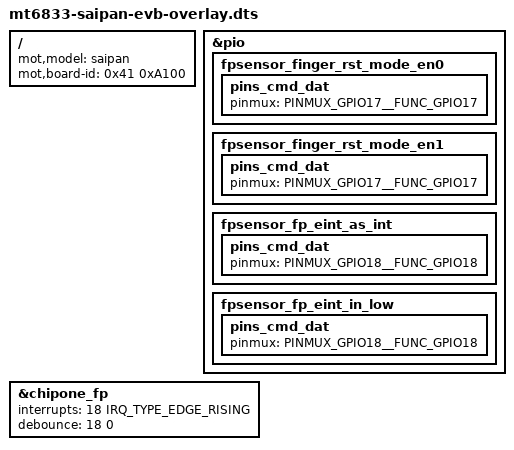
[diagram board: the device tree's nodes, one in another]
/* Copyright (c) 2019, Motorola Mobility Inc. All rights reserved.
 *
 * This program is free software; you can redistribute it and/or modify
 * it under the terms of the GNU General Public License version 2 and
 * only version 2 as published by the Free Software Foundation.
 *
 * This program is distributed in the hope that it will be useful,
 * but WITHOUT ANY WARRANTY; without even the implied warranty of
 * MERCHANTABILITY or FITNESS FOR A PARTICULAR PURPOSE.  See the
 * GNU General Public License for more details.
 */

/dts-v1/;
/plugin/;

#include "mediatek/mt6833-saipan-common-overlay.dtsi"
#include "mediatek/cust_mt6833_touch_720x1600.dtsi"

/* Board match root node */
/ {
	fragment@model {
		target-path = "/";
		__overlay__ {
			mot,model = "saipan";
			mot,board-id = <0x41 0xA100>;
		};
	};
};

&pio {
	fpsensor_finger_rst_mode_en0 {
		pins_cmd_dat {
			pinmux = <PINMUX_GPIO17__FUNC_GPIO17>;
		};
	};

	fpsensor_finger_rst_mode_en1 {
		pins_cmd_dat {
			pinmux = <PINMUX_GPIO17__FUNC_GPIO17>;
		};
	};

	fpsensor_fp_eint_as_int {
		pins_cmd_dat {
			pinmux = <PINMUX_GPIO18__FUNC_GPIO18>;
		};
	};

	fpsensor_fp_eint_in_low {
		pins_cmd_dat {
			pinmux = <PINMUX_GPIO18__FUNC_GPIO18>;
		};
	};
};

&chipone_fp {
	interrupts = <18 IRQ_TYPE_EDGE_RISING>;
	debounce = <18 0>;
};

#include <saipan_evb/cust.dtsi>
/*End of this file, DO NOT ADD ANYTHING HERE*/
